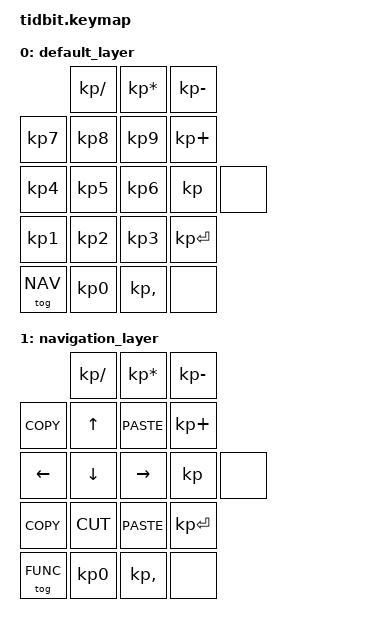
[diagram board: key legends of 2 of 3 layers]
/*
 * Copyright (c) 2020 The ZMK Contributors
 *
 * SPDX-License-Identifier: MIT
 */

#include <behaviors.dtsi>
#include <dt-bindings/zmk/bt.h>
#include <dt-bindings/zmk/outputs.h>
#include <dt-bindings/zmk/keys.h>


#define DEFAULT 0
#define NAV		1
#define FUNC    2

/ {
	

	keymap {
		compatible = "zmk,keymap";
		
		default_layer {
			bindings = <
								&kp KP_DIVIDE   &kp KP_ASTERISK &kp KP_MINUS
				&kp KP_NUMBER_7 &kp KP_NUMBER_8 &kp KP_NUMBER_9 &kp KP_PLUS
				&kp KP_NUMBER_4 &kp KP_NUMBER_5 &kp KP_NUMBER_6 &kp &none
				&kp KP_NUMBER_1 &kp KP_NUMBER_2 &kp KP_NUMBER_3 &kp KP_ENTER
				&tog NAV       &kp KP_NUMBER_0  &kp KP_COMMA    &none
			>;

		
		};

		navigation_layer {
			bindings = <
								&kp KP_DIVIDE  	&kp KP_ASTERISK &kp KP_MINUS
				&kp K_COPY 		&kp UP			&kp K_PASTE		&kp KP_PLUS
				&kp LEFT	 	&kp DOWN	 	&kp RIGHT	 	&kp &none
				&kp K_COPY 		&kp K_CUT 		&kp K_PASTE		&kp KP_ENTER
				&tog FUNC       &kp KP_NUMBER_0 &kp KP_COMMA      &none
			>;

		
		};
		
		
		 func_layer {
			 bindings = <
								&none           &reset          &bootloader
				&out OUT_TOG    &out OUT_USB    &out OUT_BLE    &none
				&bt BT_SEL 0    &bt BT_PRV      &bt BT_NXT      &bt BT_CLR
				&bt BT_SEL 1    &bt BT_SEL 2    &bt BT_SEL 3    &tog 0
				&tog DEFAULT     &none           &none           &none
			 >;

		
		 };
	};
};
